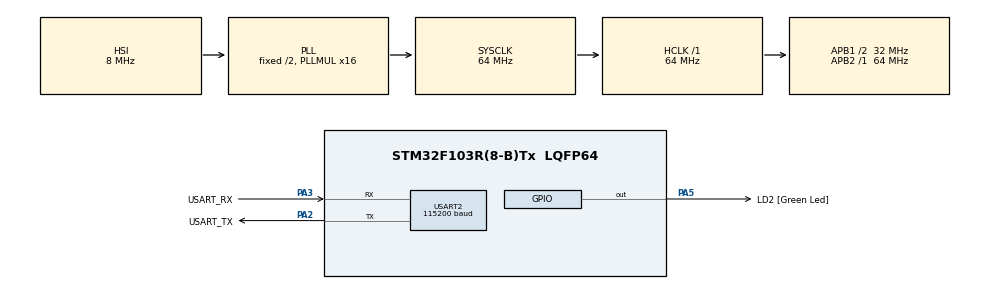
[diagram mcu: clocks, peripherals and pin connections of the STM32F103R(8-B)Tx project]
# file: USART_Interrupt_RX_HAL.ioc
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Mcu.Family=STM32F1
Mcu.Name=STM32F103R(8-B)Tx
Mcu.Package=LQFP64
NVIC.PriorityGroup=NVIC_PRIORITYGROUP_4
NVIC.USART2_IRQn=true\:1\:0\:false\:false\:true\:true\:true\:true
PA13.GPIO_Label=TMS
PA13.Mode=Serial_Wire
PA13.Signal=SYS_JTMS-SWDIO
PA14.GPIO_Label=TCK
PA14.Mode=Serial_Wire
PA14.Signal=SYS_JTCK-SWCLK
PA2.GPIO_Label=USART_TX
PA2.GPIO_Mode=GPIO_MODE_AF_PP
PA2.GPIO_PuPd=GPIO_NOPULL
PA2.GPIO_Speed=GPIO_SPEED_FREQ_LOW
PA2.Mode=Asynchronous
PA2.Signal=USART2_TX
PA3.GPIO_Label=USART_RX
PA3.GPIO_PuPd=GPIO_NOPULL
PA3.GPIO_Speed=GPIO_SPEED_FREQ_LOW
PA3.Mode=Asynchronous
PA3.Signal=USART2_RX
PA5.GPIO_Label=LD2 [Green Led]
PA5.GPIO_ModeDefaultOutputPP=GPIO_MODE_OUTPUT_PP
PA5.GPIO_PuPd=GPIO_NOPULL
PA5.GPIO_Speed=GPIO_SPEED_FREQ_LOW
PA5.Signal=GPIO_Output
PB3.GPIO_Label=SWO
PB3.Signal=SYS_JTDO-TRACESWO
PC14-OSC32_IN.Signal=RCC_OSC32_IN
PC15-OSC32_OUT.Signal=RCC_OSC32_OUT
PD0-OSC_IN.Signal=RCC_OSC_IN
PD1-OSC_OUT.Signal=RCC_OSC_OUT
ProjectManager.HeapSize=0x200
ProjectManager.StackSize=0x400
ProjectManager.TargetToolchain=STM32CubeIDE
RCC.AHBFreq_Value=64000000
RCC.APB1CLKDivider=RCC_HCLK_DIV2
RCC.APB1Freq_Value=32000000
RCC.APB1TimFreq_Value=64000000
RCC.APB2Freq_Value=64000000
RCC.APB2TimFreq_Value=64000000
RCC.HCLKFreq_Value=64000000
RCC.PLLMUL=RCC_PLL_MUL16
RCC.RTCClockSelection=RCC_RTCCLKSOURCE_LSE
RCC.SYSCLKFreq_VALUE=64000000
RCC.SYSCLKSource=RCC_SYSCLKSOURCE_PLLCLK
RCC.USBFreq_Value=64000000
USART2.BaudRate=115200
USART2.VirtualMode=VM_ASYNC
board=NUCLEO-F103RB

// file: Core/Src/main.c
/* USER CODE BEGIN Header */
/**
 ******************************************************************************
 * @file           : main.c
 * @brief          : Main program body
 ******************************************************************************
 * @attention
 *
 * Copyright (c) 2026 STMicroelectronics.
 * All rights reserved.
 *
 * This software is licensed under terms that can be found in the LICENSE file
 * in the root directory of this software component.
 * If no LICENSE file comes with this software, it is provided AS-IS.
 *
 ******************************************************************************
 */
/**
 * 02_USART_Interrupt  —  [계층: HAL]  USART2 수신 인터럽트
 *
 * 동작
 *   - PC 터미널(115200 8N1)에서 문자를 보내면 인터럽트로 1바이트씩 수신하여 에코한다.
 *   - '1' : LD2(PA5) ON, '0' : LD2 OFF, 't' : LD2 토글
 *
 * 핀 (Nucleo-F103RB, ST-Link 가상 COM 포트)
 *   USART2_TX = PA2, USART2_RX = PA3, LD2 = PA5
 *
 * 인터럽트 구조 (ISR vs 콜백)
 *   USART2_IRQHandler (stm32f1xx_it.c, 진짜 ISR)
 *     -> HAL_UART_IRQHandler()  : USART2->SR 의 RXNE / ORE 비트, CR1 의 RXNEIE 비트를 해석
 *       -> HAL_UART_RxCpltCallback() (이 파일, 사용자 콜백)  : 1바이트 수신 완료
 *   콜백은 ISR 문맥에서 실행되므로 "플래그만 세우고" 실제 처리는 main 루프에서 한다.
 */
/* USER CODE END Header */
#include "main.h"

/* USER CODE BEGIN Includes */
#include <string.h>
/* USER CODE END Includes */

UART_HandleTypeDef huart2;

/* USER CODE BEGIN PV */
static uint8_t rx_byte;               /* HAL_UART_Receive_IT 가 채워 주는 1바이트 버퍼 */
static volatile uint8_t rx_data;      /* 콜백 -> main 으로 전달하는 데이터 */
static volatile uint8_t rx_ready;     /* 콜백 -> main 으로 전달하는 플래그 */
/* USER CODE END PV */

void SystemClock_Config(void);
static void MX_GPIO_Init(void);
static void MX_USART2_UART_Init(void);

int main(void)
{

  /* MCU Configuration--------------------------------------------------------*/

  /* Reset of all peripherals, Initializes the Flash interface and the Systick. */
  HAL_Init();

  /* Configure the system clock */
  SystemClock_Config();

  /* Initialize all configured peripherals */
  MX_GPIO_Init();
  MX_USART2_UART_Init();
  /* USER CODE BEGIN 2 */
  const char *banner = "\r\n[USART2 RX interrupt] 1/0/t 를 입력하세요\r\n";
  HAL_UART_Transmit(&huart2, (uint8_t *)banner, (uint16_t)strlen(banner), 100);

  /* 수신 인터럽트 시작: USART2->CR1.RXNEIE=1, CR3.EIE=1 (HAL 내부에서 설정) */
  HAL_UART_Receive_IT(&huart2, &rx_byte, 1);
  /* USER CODE END 2 */

  /* Infinite loop */
  while (1)
  {

    /* USER CODE BEGIN 3 */
    if (rx_ready)
    {
      uint8_t c = rx_data;
      rx_ready = 0;

      switch (c)
      {
      case '1': HAL_GPIO_WritePin(LD2_GPIO_Port, LD2_Pin, GPIO_PIN_SET);   break;  /* GPIOA->BSRR 로 set */
      case '0': HAL_GPIO_WritePin(LD2_GPIO_Port, LD2_Pin, GPIO_PIN_RESET); break;  /* GPIOA->BSRR 로 reset */
      case 't': HAL_GPIO_TogglePin(LD2_GPIO_Port, LD2_Pin);                break;  /* GPIOA->ODR XOR */
      default: break;
      }
      HAL_UART_Transmit(&huart2, &c, 1, 100);   /* 에코 (main 문맥에서 블로킹 송신) */
    }
  }
  /* USER CODE END 3 */
}

void SystemClock_Config(void)
{
  RCC_OscInitTypeDef RCC_OscInitStruct = {0};
  RCC_ClkInitTypeDef RCC_ClkInitStruct = {0};

  /** Initializes the RCC Oscillators according to the specified parameters
  * in the RCC_OscInitTypeDef structure.
  */
  RCC_OscInitStruct.OscillatorType = RCC_OSCILLATORTYPE_HSI;
  RCC_OscInitStruct.HSIState = RCC_HSI_ON;
  RCC_OscInitStruct.HSICalibrationValue = RCC_HSICALIBRATION_DEFAULT;
  RCC_OscInitStruct.PLL.PLLState = RCC_PLL_ON;
  RCC_OscInitStruct.PLL.PLLSource = RCC_PLLSOURCE_HSI_DIV2;
  RCC_OscInitStruct.PLL.PLLMUL = RCC_PLL_MUL16;
  if (HAL_RCC_OscConfig(&RCC_OscInitStruct) != HAL_OK)
  {
    Error_Handler();
  }

  /** Initializes the CPU, AHB and APB buses clocks
  */
  RCC_ClkInitStruct.ClockType = RCC_CLOCKTYPE_HCLK|RCC_CLOCKTYPE_SYSCLK
                              |RCC_CLOCKTYPE_PCLK1|RCC_CLOCKTYPE_PCLK2;
  RCC_ClkInitStruct.SYSCLKSource = RCC_SYSCLKSOURCE_PLLCLK;
  RCC_ClkInitStruct.AHBCLKDivider = RCC_SYSCLK_DIV1;
  RCC_ClkInitStruct.APB1CLKDivider = RCC_HCLK_DIV2;
  RCC_ClkInitStruct.APB2CLKDivider = RCC_HCLK_DIV1;

  if (HAL_RCC_ClockConfig(&RCC_ClkInitStruct, FLASH_LATENCY_2) != HAL_OK)
  {
    Error_Handler();
  }
}

static void MX_USART2_UART_Init(void)
{

  huart2.Instance = USART2;
  huart2.Init.BaudRate = 115200;
  huart2.Init.WordLength = UART_WORDLENGTH_8B;
  huart2.Init.StopBits = UART_STOPBITS_1;
  huart2.Init.Parity = UART_PARITY_NONE;
  huart2.Init.Mode = UART_MODE_TX_RX;
  huart2.Init.HwFlowCtl = UART_HWCONTROL_NONE;
  huart2.Init.OverSampling = UART_OVERSAMPLING_16;
  if (HAL_UART_Init(&huart2) != HAL_OK)
  {
    Error_Handler();
  }

}

static void MX_GPIO_Init(void)
{
  GPIO_InitTypeDef GPIO_InitStruct = {0};

  /* GPIO Ports Clock Enable */
  __HAL_RCC_GPIOC_CLK_ENABLE();
  __HAL_RCC_GPIOD_CLK_ENABLE();
  __HAL_RCC_GPIOA_CLK_ENABLE();
  __HAL_RCC_GPIOB_CLK_ENABLE();

  /*Configure GPIO pin Output Level */
  HAL_GPIO_WritePin(LD2_GPIO_Port, LD2_Pin, GPIO_PIN_RESET);

  /*Configure GPIO pin : LD2_Pin */
  GPIO_InitStruct.Pin = LD2_Pin;
  GPIO_InitStruct.Mode = GPIO_MODE_OUTPUT_PP;
  GPIO_InitStruct.Pull = GPIO_NOPULL;
  GPIO_InitStruct.Speed = GPIO_SPEED_FREQ_LOW;
  HAL_GPIO_Init(LD2_GPIO_Port, &GPIO_InitStruct);

}

/* USER CODE BEGIN 4 */
/* -------------------------------------------------------------------------- */
/* HAL 콜백 (ISR 이 아님): USART2_IRQHandler -> HAL_UART_IRQHandler 가 ISR 문맥에서  */
/* 호출해 주는 함수. 데이터/플래그만 저장하고 실제 처리는 main 루프에서 한다.        */
/* -------------------------------------------------------------------------- */
void HAL_UART_RxCpltCallback(UART_HandleTypeDef *huart)
{
  if (huart->Instance == USART2)
  {
    rx_data = rx_byte;
    rx_ready = 1;  //flag set: main 루프에서 처리하도록 알림
    HAL_UART_Receive_IT(&huart2, &rx_byte, 1);   /* 다음 바이트를 위해 재무장(필수) */
  }
}

/* 오버런/프레이밍 오류(SR.ORE/FE)가 나면 HAL 이 수신을 중단하므로 여기서 다시 시작한다 */
void HAL_UART_ErrorCallback(UART_HandleTypeDef *huart)
{
  if (huart->Instance == USART2)
  {
    HAL_UART_Receive_IT(&huart2, &rx_byte, 1);
  }
}
/* USER CODE END 4 */

void Error_Handler(void)
{
  __disable_irq();
  while (1) {
  }
}
#ifdef USE_FULL_ASSERT
/**
  * @brief  Reports the name of the source file and the source line number
  *         where the assert_param error has occurred.
  * @param  file: pointer to the source file name
  * @param  line: assert_param error line source number
  * @retval None
  */
void assert_failed(uint8_t *file, uint32_t line)
{
  /* USER CODE BEGIN 6 */
  /* User can add his own implementation to report the file name and line
     number, ex: printf("Wrong parameters value: file %s on line %d\r\n", file,
     line) */
  /* USER CODE END 6 */
}
#endif /* USE_FULL_ASSERT */
